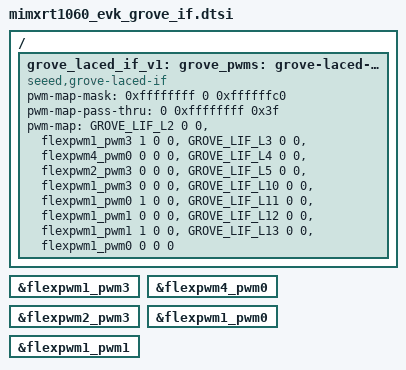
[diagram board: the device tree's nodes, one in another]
/*
 * SPDX-FileCopyrightText: Copyright (c) 2023-2026 TiaC Systems
 * SPDX-License-Identifier: Apache-2.0
 */

#include <zephyr/dt-bindings/gpio/grove-laced-if.h>

/ {
	grove_laced_if_v1: grove-laced-if-v1 {
		compatible = "seeed,grove-laced-if";

		#pwm-cells = <3>;
		pwm-map-mask = <0xffffffff 0 0xffffffc0>;
		pwm-map-pass-thru = <0 0xffffffff 0x3f>;
		pwm-map =
			/*  0 - D0: not possible */
			/*  1 - D1: not possible */
			<GROVE_LIF_L2 0 0 &flexpwm1_pwm3 1 0 0>, /* D2: PWM1B3 */
			<GROVE_LIF_L3 0 0 &flexpwm4_pwm0 0 0 0>, /* D3: PWM4A0 */
			<GROVE_LIF_L4 0 0 &flexpwm2_pwm3 0 0 0>, /* D4: PWM2A3 */
			<GROVE_LIF_L5 0 0 &flexpwm1_pwm3 0 0 0>, /* D5: PWM1A3 */
			/*  6 - D6: not possible */
			/*  7 - D7: not possible */
			/*  8 - D8: not possible */
			/*  9 - D9: not possible */
/* (SDMMC-CLK) */	<GROVE_LIF_L10 0 0 &flexpwm1_pwm0 1 0 0>, /* D10: PWM1B0 */
/* (SDMMC-D0) */	<GROVE_LIF_L11 0 0 &flexpwm1_pwm1 0 0 0>, /* D11: PWM1A1 */
/* (SDMMC-D1) */	<GROVE_LIF_L12 0 0 &flexpwm1_pwm1 1 0 0>, /* D12: PWM1B1 */
/* (SDMMC-CMD) */	<GROVE_LIF_L13 0 0 &flexpwm1_pwm0 0 0 0>; /* D13: PWM1A0 */
			/* 14 - D14: not possible */
			/* 15 - D15: not possible */
			/* 16 - D16: not possible */
			/* 17 - D17: not possible */
			/* 18 - D18: not possible */
			/* 19 - D19: not possible */
	};
};

grove_pwms: &grove_laced_if_v1 {};

grove_pwm_d2: &flexpwm1_pwm3 {};
grove_pwm_d3: &flexpwm4_pwm0 {};
grove_pwm_d4: &flexpwm2_pwm3 {};
grove_pwm_d5: &flexpwm1_pwm3 {};
grove_pwm_d10: &flexpwm1_pwm0 {};
grove_pwm_d11: &flexpwm1_pwm1 {};
grove_pwm_d12: &flexpwm1_pwm1 {};
grove_pwm_d13: &flexpwm1_pwm0 {};
